# MM32F031xxn register map
File version: 1.92
CPU: CM0 r0p0, little endian, no MPU, no FPU, 2 interrupt priority bits
Registers are 32-bit, read-write, reset 0x0 unless marked. A register's access mark holds for its fields unless they carry their own. Offsets are from the block's base; [hi:lo] are bit positions; {n}, {i} and the like mark numbered series; 'fields as' and 'values as' point back to an identical list.

## DMA1 — DMA1 controller
Base 0x40020000
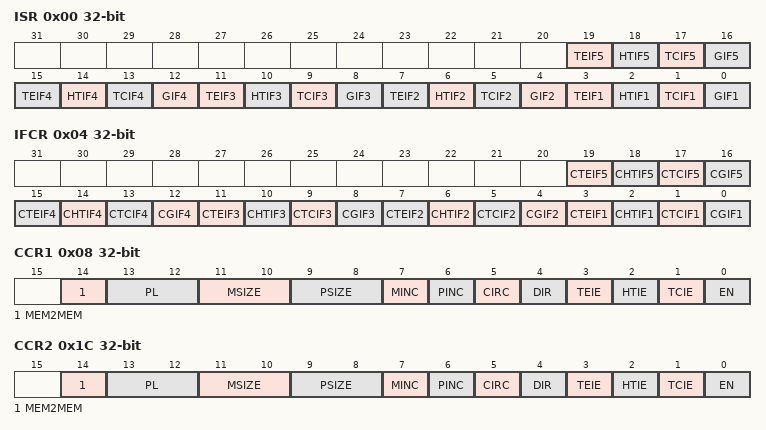
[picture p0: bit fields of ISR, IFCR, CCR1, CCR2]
0x00 ISR ro
  [4n-1] TEIF{n} (n=1..5) — channel {n} transfer error flag
  [4n-2] HTIF{n} (n=1..5) — channel {n} half transfer flag
  [4n-3] TCIF{n} (n=1..5) — channel {n} transfer complete flag
  [4n-4] GIF{n} (n=1..5) — channel {n} global interrupt flag
0x04 IFCR
  [4n-1] CTEIF{n} (n=1..5) — channel {n} transfer error clear
  [4n-2] CHTIF{n} (n=1..5) — channel {n} half transfer clear
  [4n-3] CTCIF{n} (n=1..5) — channel {n} transfer complete clear
  [4n-4] CGIF{n} (n=1..5) — channel {n} global interrupt clear
0x08 CCR1
  [14] MEM2MEM — Memory to memory mode
  [13:12] PL — Channel priority level
  [11:10] MSIZE — Memory size
  [9:8] PSIZE — Peripheral size
  [7] MINC — Memory increment mode
  [6] PINC — Peripheral increment mode
  [5] CIRC — Circular mode
  [4] DIR — Data transfer direction
  [3] TEIE — Transfer error interrupt enable
  [2] HTIE — Half transfer interrupt enable
  [1] TCIE — Transfer complete interrupt enable
  [0] EN — Channel enable
0x0C CNDTR1
  [15:0] NDT — Number of data to transfer
0x10 CPAR1
  [31:0] PA — Peripheral address
{0x0+0x14*i} CMAR{i} (i=1..5)
  [31:0] MA — Memory address
0x1C CCR2
  fields as CCR1
0x20 CNDTR2
  [15:0] NDT — Number of data to transfer
0x24 CPAR2
  [31:0] PA — Peripheral address
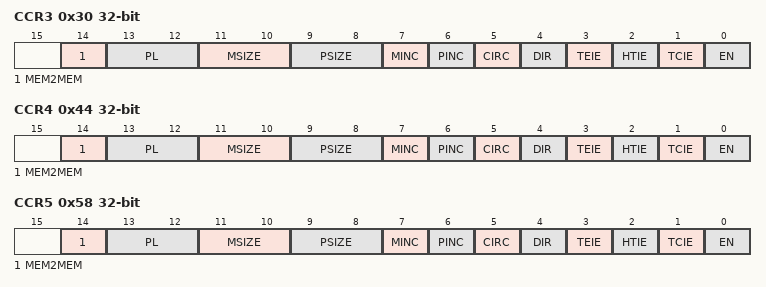
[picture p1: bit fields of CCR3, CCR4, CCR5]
0x30 CCR3
  fields as CCR1
0x34 CNDTR3
  [15:0] NDT — Number of data to transfer
0x38 CPAR3
  [31:0] PA — Peripheral address
0x44 CCR4
  fields as CCR1
0x48 CNDTR4
  [15:0] NDT — Number of data to transfer
0x4C CPAR4
  [31:0] PA — Peripheral address
0x58 CCR5
  fields as CCR1
0x5C CNDTR5
  [15:0] NDT — Number of data to transfer
0x60 CPAR5
  [31:0] PA — Peripheral address

## EXTI — External interrupt/event controller
Base 0x40010000
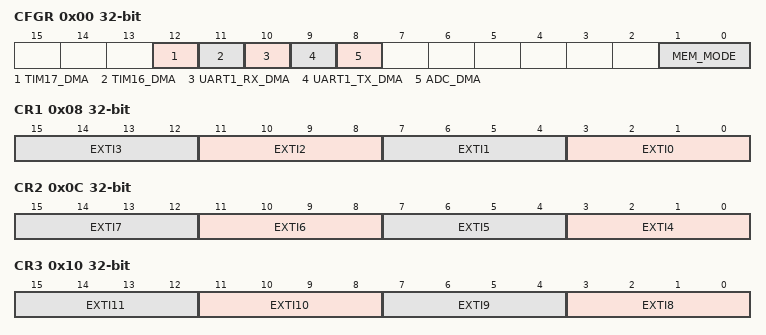
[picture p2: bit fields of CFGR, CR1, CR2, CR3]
0x00 CFGR — Configuration register
  [12] TIM17_DMA — TIM17_DMA_RMP
  [11] TIM16_DMA — TIM16_DMA_RMP
  [10] UART1_RX_DMA — UART1_RX_DMA_RMP
  [9] UART1_TX_DMA — UART1_TX_DMA_RMP
  [8] ADC_DMA — ADC_DMA_RMP
  [1:0] MEM_MODE
0x08 CR1 — External interrupt configuration register 1
  [4n+3:4n] EXTI{n} (n=0..3) — EXTI{n} configuration
0x0C CR2 — External interrupt configuration register 2
  [4n-13:4n-16] EXTI{n} (n=4..7) — EXTI{n} configuration
0x10 CR3 — External interrupt configuration register 3
  [4n-29:4n-32] EXTI{n} (n=8..11) — EXTI{n} configuration
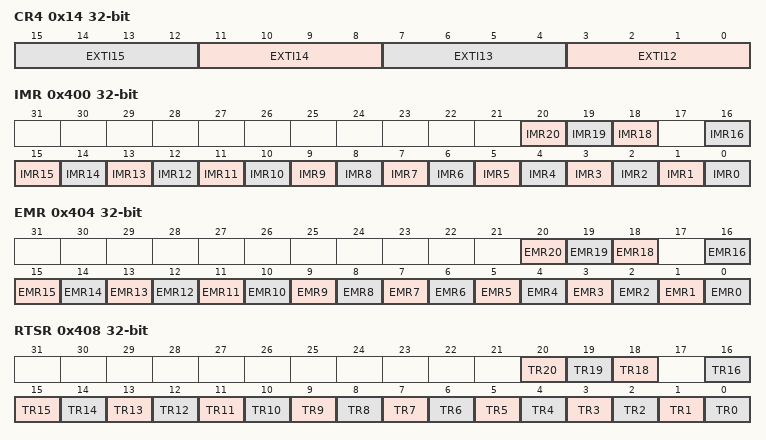
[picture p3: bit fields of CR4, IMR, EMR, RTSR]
0x14 CR4 — External interrupt configuration register 4
  [4n-45:4n-48] EXTI{n} (n=12..15) — EXTI{n} configuration
0x400 IMR — Interrupt mask register
  [20] IMR20 — Interrupt Mask on line 20
  [19] IMR19 — Interrupt Mask on line 19
  [18] IMR18 — Interrupt Mask on line 18
  [n] IMR{n} (n=0..16) — Interrupt Mask on line {n}
0x404 EMR — Event mask register
  [20] EMR20 — Event Mask on line 20
  [19] EMR19 — Event Mask on line 19
  [18] EMR18 — Event Mask on line 18
  [n] EMR{n} (n=0..16) — Event Mask on line {n}
0x408 RTSR — Rising trigger selection register
  [20] TR20 — Rising trigger event configuration bit of line 20
  [19] TR19 — Rising trigger event configuration bit of line 19
  [18] TR18 — Rising trigger event configuration bit of line 18
  [n] TR{n} (n=0..16) — Rising trigger event configuration bit of line {n}
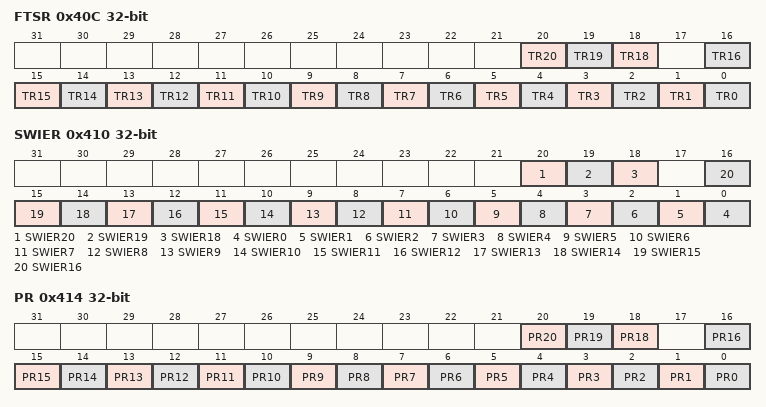
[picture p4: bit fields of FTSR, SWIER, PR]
0x40C FTSR — Falling trigger selection register
  [20] TR20 — Falling trigger event configuration bit of line 20
  [19] TR19 — Falling trigger event configuration bit of line 19
  [18] TR18 — Falling trigger event configuration bit of line 18
  [n] TR{n} (n=0..16) — Falling trigger event configuration bit of line {n}
0x410 SWIER — Software interrupt event register
  [20] SWIER20 — Software interrupt on line 20
  [19] SWIER19 — Software interrupt on line 19
  [18] SWIER18 — Software interrupt on line 18
  [n] SWIER{n} (n=0..16) — Software interrupt on line {n}
0x414 PR — Pending register
  [20] PR20 — Pending bit
  [19] PR19 — Pending bit
  [18] PR18 — Pending bit
  [n] PR{n} (n=0..16) — Pending bit
